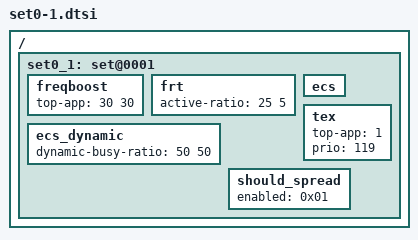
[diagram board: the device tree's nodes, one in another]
/ {
	/* normal mode - touch boost */
	set0_1: set@0001 {
		/* Boosting margin applied to frequency selection */
		freqboost {	   		/* LIT BIG */
			top-app         	= < 30  30>;
		};

		frt {	   			/* LIT BIG */
			active-ratio 		= < 25   5>;
		};

		ecs { };

		ecs_dynamic {
			dynamic-busy-ratio		= <50 50>;
		};

		tex {
			top-app = <1>;
			prio = <119>;
		};

		should_spread {
			enabled = <0x01>;
		};
	};
};
